# Z32F3841 register map
Vendor: Zilog, Inc; File version: 1.0.1
CPU: CM3 r2p0, little endian, no MPU, no FPU, 3 interrupt priority bits
Registers are 32-bit, read-write, reset 0x0 unless marked. A register's access mark holds for its fields unless they carry their own. Offsets are from the block's base; [hi:lo] are bit positions; {n}, {i} and the like mark numbered series; 'fields as' and 'values as' point back to an identical list.

## SCU — SYSTEM CONTROL UNIT
Base 0x40000000
0x00 CIDR ro reset 0xAC330384 — Chip ID Register
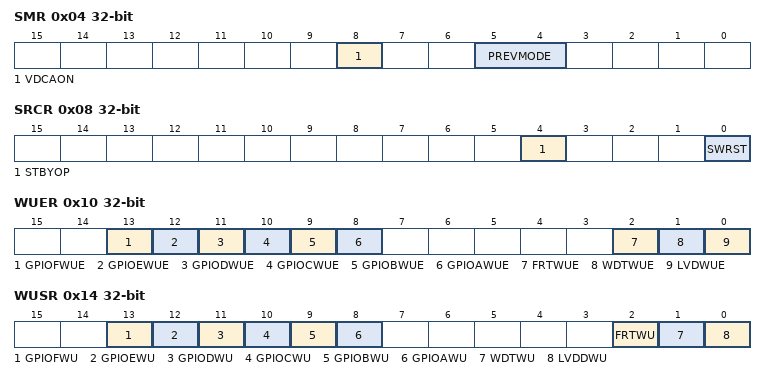
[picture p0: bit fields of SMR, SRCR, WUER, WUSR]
0x04 SMR — System Mode Register
  [8] VDCAON, [5:4] PREVMODE
0x08 SRCR — System Reset Control Register
  [4] STBYOP — STBOP pin output polarity select bit
  [0] SWRST wo — Internal soft reset activation
0x0C CIDR2 ro reset 0x2 — Revision ID Register
0x10 WUER — Wakeup Source Enable Register
  [13] GPIOFWUE, [12] GPIOEWUE, [11] GPIODWUE, [10] GPIOCWUE, [9] GPIOBWUE, [8] GPIOAWUE, [2] FRTWUE, [1] WDTWUE, [0] LVDWUE
0x14 WUSR ro — Wakeup Source Status Register
  [13] GPIOFWU
  [12] GPIOEWU
  [11] GPIODWU
  [10] GPIOCWU
  [9] GPIOBWU
  [8] GPIOAWU
  [2] FRTWU
  [1] WDTWU
  [0] LVDDWU — LVDWU
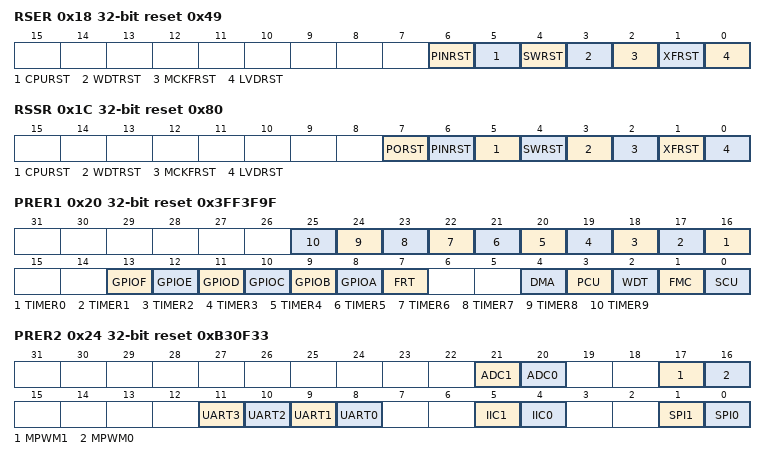
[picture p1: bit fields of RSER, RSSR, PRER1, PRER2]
0x18 RSER reset 0x49 — Reset Source Enable Register
  [6] PINRST — external pin reset enable
  [5] CPURST — CPU request reset enable
  [4] SWRST — software reset enable
  [3] WDTRST — watch dog reset enable
  [2] MCKFRST — MCLK failed reset enable
  [1] XFRST — external OSC clock failed enable
  [0] LVDRST — LVD reset enable
0x1C RSSR reset 0x80 — Reset Source Status Register
  [7] PORST — power on reset status
  [6] PINRST — extenral pin reset status
  [5] CPURST — cpu request reset status
  [4] SWRST — software reset status
  [3] WDTRST — watchdog timer reset status
  [2] MCKFRST — MCLK failed reset status
  [1] XFRST — clock failed reset status
  [0] LVDRST — lvd reset status
0x20 PRER1 reset 0x3FF3F9F — Peripheral Reset Enable Register 1
  [n+16] TIMER{n} (n=0..9) — TIMER{n} Reset
  [13] GPIOF — GPIOF Reset
  [12] GPIOE — GPIOE Reset
  [11] GPIOD — GPIOD Reset
  [10] GPIOC — GPIOC Reset
  [9] GPIOB — GPIOB Reset
  [8] GPIOA — GPIOA Reset
  [7] FRT — FRT Reset
  [4] DMA — DMA Reset
  [3] PCU — Port controll Reset
  [2] WDT — Watch Dog Timer Reset
  [1] FMC — Flash Memory controll Reset
  [0] SCU — Power Management Unit Reset
0x24 PRER2 reset 0xB30F33 — Peripheral Reset Enable Register 2
  [21] ADC1 — ADC1 Reset
  [20] ADC0 — ADC0 Reset
  [17] MPWM1 — MPWM1 Reset
  [16] MPWM0 — MPWM0 Reset
  [11] UART3
  [10] UART2
  [9] UART1
  [8] UART0 — UART0 Reset
  [5] IIC1 — IIC1 Reset
  [4] IIC0 — IIC0 Reset
  [1] SPI1 — SPI1 Reset
  [0] SPI0 — SPI0 Reset
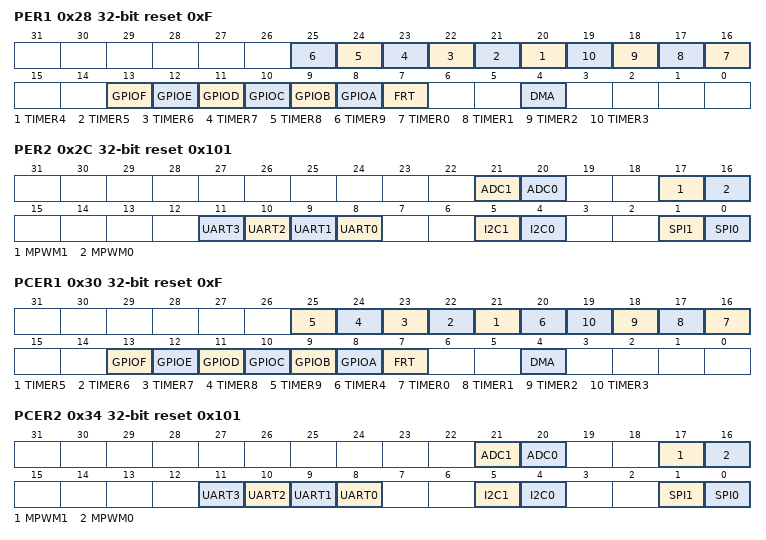
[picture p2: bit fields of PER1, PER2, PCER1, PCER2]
0x28 PER1 reset 0xF — Peripheral Enable Register 1
  [n+16] TIMER{n} (n=4..9) — TIMER{n} Enable
  [n+16] TIMER{n} (n=0..3)
  [13] GPIOF
  [12] GPIOE
  [11] GPIOD
  [10] GPIOC
  [9] GPIOB
  [8] GPIOA
  [7] FRT
  [4] DMA — DMA Function Enable
0x2C PER2 reset 0x101 — Peripheral Enable Register 2
  [21] ADC1
  [20] ADC0
  [17] MPWM1 — MPWM1 Enable
  [16] MPWM0 — MPWM0 Enable
  [n+8] UART{n} (n=0..3) — UART{n} Enable
  [5] I2C1 — I2C1 Enable
  [4] I2C0 — I2C0 Enable
  [1] SPI1 — SPI1 Enable
  [0] SPI0 — SPI0 Enable
0x30 PCER1 reset 0xF — Peripheral Clock Enable Register 1
  [n+16] TIMER{n} (n=5..9) — TIMER{n} Enable
  [20] TIMER4 — TIMER5 Enable
  [n+16] TIMER{n} (n=0..3)
  [13] GPIOF
  [12] GPIOE
  [11] GPIOD
  [10] GPIOC
  [9] GPIOB
  [8] GPIOA
  [7] FRT — FRT Enable
  [4] DMA — DMA Function Enable
0x34 PCER2 reset 0x101 — Peripheral Clock Enable Register 2
  fields as PER2
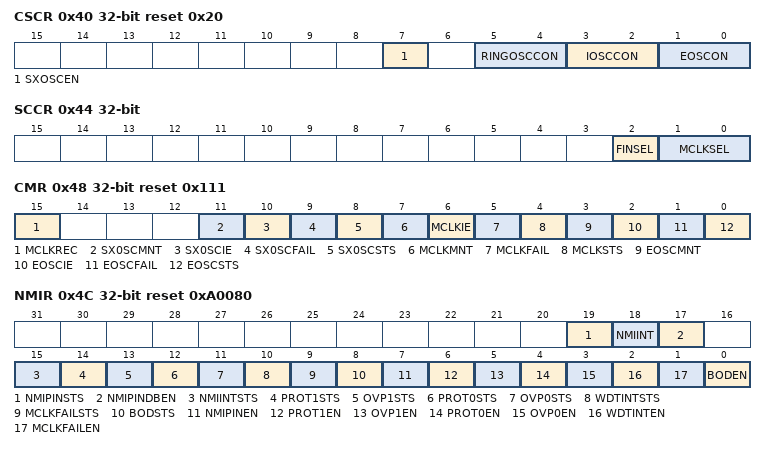
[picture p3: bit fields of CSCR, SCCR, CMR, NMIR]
0x40 CSCR reset 0x20 — Clock Source Control Register
  [7] SXOSCEN — External Sub Oscillator Enable
  [5:4] RINGOSCCON — Internal ring OSC control
  [3:2] IOSCCON — Internal OSC control
  [1:0] EOSCON — External crystal OSC control
0x44 SCCR — System Clock Control Register
  [2] FINSEL — PLL Input source FIN Select
  [1:0] MCLKSEL — System clock select
0x48 CMR reset 0x111 — Clock Monitoring Register
  [15] MCLKREC ro — MCLK failed auto recovery
  [11] SX0SCMNT — Sub Oscillator Monitoring Enable
  [10] SX0SCIE — Sub Oscillator Fail Interrupt Enable
  [9] SX0SCFAIL — Sub Oscillator Fail Interrupt
  [8] SX0SCSTS — Sub Oscillator clock status
  [7] MCLKMNT — MCLK monitor enable
  [6] MCLKIE — MCLK fail Interrupt enable
  [5] MCLKFAIL — MCLK Failed flag
  [4] MCLKSTS — MCLK clock status
  [3] EOSCMNT — Externaler OSC monitor enable
  [2] EOSCIE — external OSC failed interrupt enable
  [1] EOSCFAIL — external OSC failed flag
  [0] EOSCSTS — external OSC status
0x4C NMIR reset 0xA0080 — NMI Control Register
  [19] NMIPINSTS ro — NMI Pin status
  [18] NMIINT — NMI Interrupt state
  [17] NMIPINDBEN — NMI Pin Debounce status
  [15] NMIINTSTS ro — NMI Interrupt Status
  [14] PROT1STS ro — Protection condition status
  [13] OVP1STS ro — Over Voltage Protection Status
  [12] PROT0STS ro — Protection condition status
  [11] OVP0STS ro — Over Voltage Protection Status
  [10] WDTINTSTS ro — Watch Dog status
  [9] MCLKFAILSTS ro — MCLK Fail Status
  [8] BODSTS ro — Brown Out Detect Status
  [7] NMIPINEN — NMI Pin Enable
  [6] PROT1EN — Protection Condition NMI Enable
  [5] OVP1EN — Over Voltage Protection NMI Enable
  [4] PROT0EN — Protection Condition NMI Enable
  [3] OVP0EN — Over Voltage Protection NMI Enable
  [2] WDTINTEN — WDT interrupt for NMI Enable
  [1] MCLKFAILEN — MCLK Fail NMI Enable
  [0] BODEN — Brown Out Dectect NMI Enable
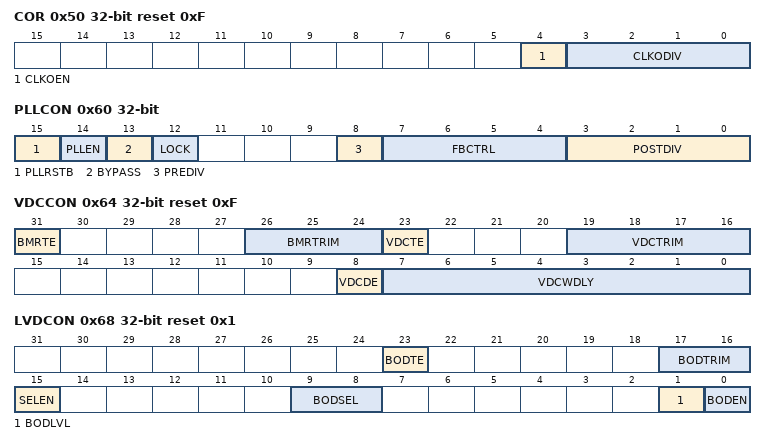
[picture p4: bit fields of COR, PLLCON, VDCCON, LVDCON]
0x50 COR reset 0xF — Clock Output Register
  [4] CLKOEN — clock output enable
  [3:0] CLKODIV — clock output divider value
0x60 PLLCON — PLL Control Register
  [15] PLLRSTB — PLL reset
  [14] PLLEN — PLL Enable
  [13] BYPASS — FIN Bypass to FOUT
  [12] LOCK ro — PLL Lock state
  [8] PREDIV — FIN pre divider
  [7:4] FBCTRL — Feedback control
  [3:0] POSTDIV — post divider
0x64 VDCCON reset 0xF — VDC Control Register
  [31] BMRTE wo
  [26:24] BMRTRIM
  [23] VDCTE wo — VDC Trim Write Enable
  [19:16] VDCTRIM
  [8] VDCDE wo
  [7:0] VDCWDLY — VDC warm up delay count
0x68 LVDCON reset 0x1 — Brown out detect Control Register
  [23] BODTE wo
  [17:16] BODTRIM
  [15] SELEN
  [9:8] BODSEL — Brown Out Level Select
  [1] BODLVL ro
  [0] BODEN — Brown out detection Enable
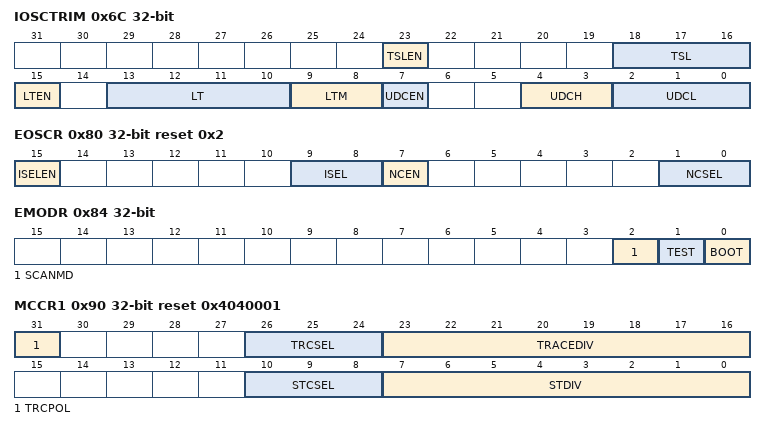
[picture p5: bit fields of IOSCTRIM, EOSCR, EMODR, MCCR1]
0x6C IOSCTRIM — Internal OSC Trim Register
  [23] TSLEN
  [18:16] TSL
  [15] LTEN
  [13:10] LT — interal oscillator LT trim value
  [9:8] LTM — interal oscillator LT trim value
  [7] UDCEN
  [4:3] UDCH
  [2:0] UDCL
0x80 EOSCR reset 0x2 — External Oscillator Control Register
  [15] ISELEN wo — write enable for bit field ISEL
  [9:8] ISEL — select current
  [7] NCEN wo — write enable for Noise Canceling delay
  [1:0] NCSEL — Select Noise Canceling delay
0x84 EMODR ro — External Mode Status Register
  [2] SCANMD — scan mode pin level
  [1] TEST — TEST PIN level
  [0] BOOT — boot pin level
0x90 MCCR1 reset 0x4040001 — Trace and SysTick Clock Control Register
  [31] TRCPOL wo
  [26:24] TRCSEL — trace clock source sel
  [23:16] TRACEDIV
  [10:8] STCSEL — systick clock source sel
  [7:0] STDIV — systick divider
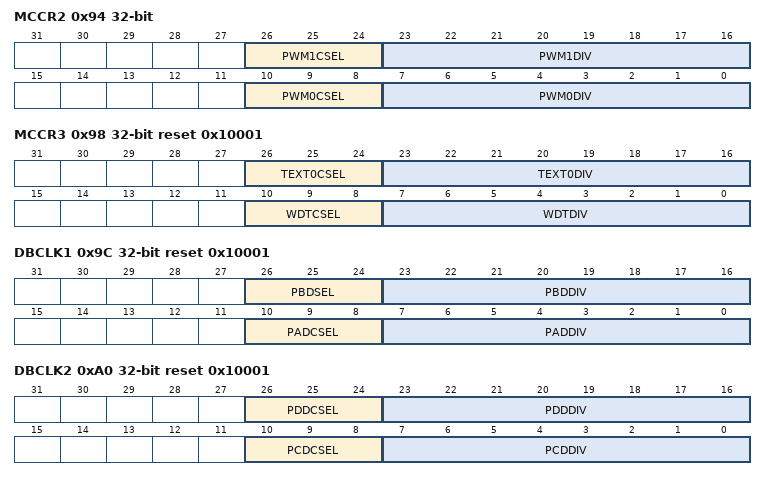
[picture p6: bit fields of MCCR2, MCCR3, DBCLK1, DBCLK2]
0x94 MCCR2 — MPWM0 and MPWM1 Clock Control Register
  [26:24] PWM1CSEL — PWM1 clock sel
  [23:16] PWM1DIV — pwm1 divider
  [10:8] PWM0CSEL — pwm0 clock sel
  [7:0] PWM0DIV — PWM0 divider
0x98 MCCR3 reset 0x10001 — TEXT0 and WDT clock control registers
  [26:24] TEXT0CSEL — timer ext0 clock sel
  [23:16] TEXT0DIV — timer ext0 divider
  [10:8] WDTCSEL — WDT clock sel
  [7:0] WDTDIV — WDT divider
0x9C DBCLK1 reset 0x10001 — PA and PB Debounce Clock Control Register
  [26:24] PBDSEL — debouce clock for port B source clock sel
  [23:16] PBDDIV — PORT B debounce divider
  [10:8] PADCSEL — debouce clock for port A source clock sel
  [7:0] PADDIV — PORT A debounce divider
0xA0 DBCLK2 reset 0x10001 — PC and PD Debounce Control Register
  [26:24] PDDCSEL — debouce clock for port D source clock sel
  [23:16] PDDDIV — PORT D debounce divider
  [10:8] PCDCSEL — debouce clock for port C source clock sel
  [7:0] PCDDIV — PORT C debounce divider
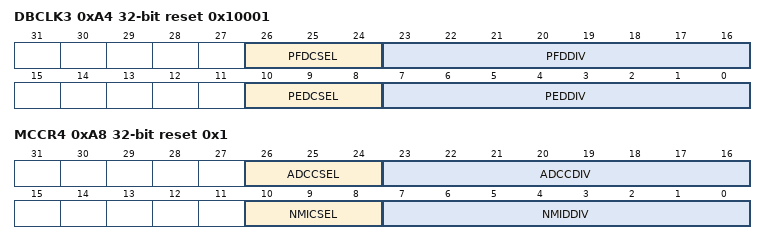
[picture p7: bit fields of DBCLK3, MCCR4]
0xA4 DBCLK3 reset 0x10001 — PE and PF Debounce Clock Control
  [26:24] PFDCSEL — Debounce Clock for PORT F source select bitl
  [23:16] PFDDIV — PORT F Clock N divider
  [10:8] PEDCSEL — Debouce clock for PORT E source select bit
  [7:0] PEDDIV — PORT E Debounce clock divider
0xA8 MCCR4 reset 0x1 — Alternative ADC and NMI Debounce Clock control
  [26:24] ADCCSEL — ADC clock source select
  [23:16] ADCCDIV — ADC Clock N divider
  [10:8] NMICSEL — Debouce clock for NMI source select bit
  [7:0] NMIDDIV — NMI Debounce clock divider
